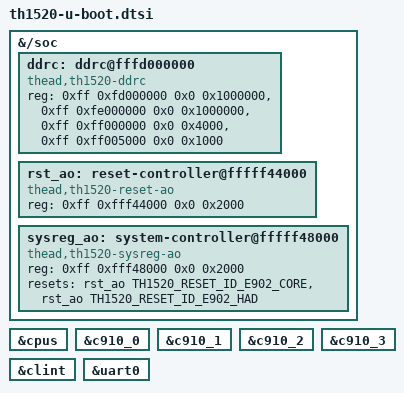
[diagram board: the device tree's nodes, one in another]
// SPDX-License-Identifier: GPL-2.0
/*
 * Copyright (C) 2025 Yao Zi <ziyao@disroot.org>
 */

#include <dt-bindings/reset/thead,th1520-reset.h>

&{/soc} {
	ddrc: ddrc@fffd000000 {
		compatible = "thead,th1520-ddrc";
		reg = <0xff 0xfd000000 0x0 0x1000000>,
		      <0xff 0xfe000000 0x0 0x1000000>,
		      <0xff 0xff000000 0x0 0x4000>,
		      <0xff 0xff005000 0x0 0x1000>;
		reg-names = "phy-0", "phy-1", "ctrl", "sys";
		bootph-pre-ram;
	};

	rst_ao: reset-controller@fffff44000 {
		compatible = "thead,th1520-reset-ao";
		reg = <0xff 0xfff44000 0x0 0x2000>;
		#reset-cells = <1>;
		status = "okay";
	};

	sysreg_ao: system-controller@fffff48000 {
		compatible = "thead,th1520-sysreg-ao";
		reg = <0xff 0xfff48000 0x0 0x2000>;
		resets = <&rst_ao TH1520_RESET_ID_E902_CORE>,
			 <&rst_ao TH1520_RESET_ID_E902_HAD>;
		reset-names = "core", "had";
		status = "okay";
	};
};

&cpus {
	bootph-pre-ram;
};

&c910_0 {
	bootph-pre-ram;
};

&c910_1 {
	bootph-pre-ram;
};

&c910_2 {
	bootph-pre-ram;
};

&c910_3 {
	bootph-pre-ram;
};

&clint {
	bootph-pre-ram;
};

&uart0 {
	bootph-pre-ram;
};
